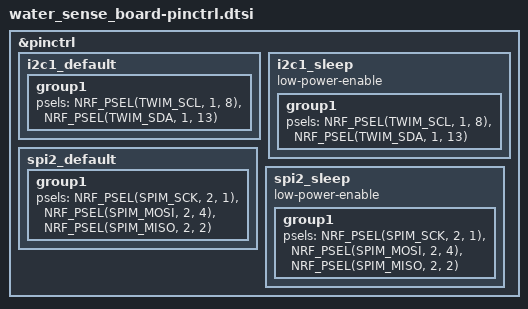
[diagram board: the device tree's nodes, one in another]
&pinctrl {

  i2c1_default: i2c1_default {
    group1 {
      psels = <NRF_PSEL(TWIM_SCL, 1, 8)>,
              <NRF_PSEL(TWIM_SDA, 1, 13)>;
    };
  };

  i2c1_sleep: i2c1_sleep {
    group1 {
      psels = <NRF_PSEL(TWIM_SCL, 1, 8)>,
              <NRF_PSEL(TWIM_SDA, 1, 13)>;
    };
    low-power-enable;
  };

  spi2_default: spi2_default {
    group1 {
      psels = <NRF_PSEL(SPIM_SCK, 2, 1)>,
              <NRF_PSEL(SPIM_MOSI, 2, 4)>,
              <NRF_PSEL(SPIM_MISO, 2, 2)>;
    };
  };

  spi2_sleep: spi2_sleep {
    group1 {
      psels = <NRF_PSEL(SPIM_SCK, 2, 1)>,
              <NRF_PSEL(SPIM_MOSI, 2, 4)>,
              <NRF_PSEL(SPIM_MISO, 2, 2)>;
    };
    low-power-enable;
  };
};
